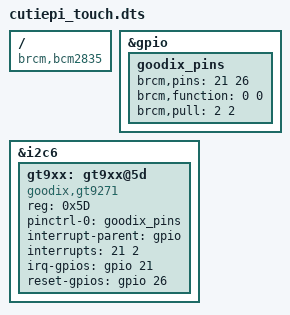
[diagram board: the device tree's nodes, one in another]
// Device tree overlay for I2C connected Goodix gt9xx multiple touch controller
// For resolution 800x1280 MIPI display
/dts-v1/;
/plugin/;

/ {
        compatible = "brcm,bcm2835";

        fragment@0 {
                target = <&gpio>;
                __overlay__ {
                        goodix_pins: goodix_pins {
                                brcm,pins = <21 26>; // interrupt and reset
                                brcm,function = <0 0>; // in
                                brcm,pull = <2 2>; // pull-up
                        };
                };
        };

        fragment@1 {
                target = <&i2c6>;
                __overlay__ {
                        #address-cells = <1>;
                        #size-cells = <0>;
                        status = "okay";

                        gt9xx: gt9xx@5d {
                                compatible = "goodix,gt9271";  // can also add others here
                                reg = <0x5D>;
                                pinctrl-names = "default";
                                pinctrl-0 = <&goodix_pins>;
                                interrupt-parent = <&gpio>;
                                interrupts = <21 2>; // high-to-low edge triggered
                                irq-gpios = <&gpio 21 0>; 
                                reset-gpios = <&gpio 26 0>;
                        };
                };
        };
};

